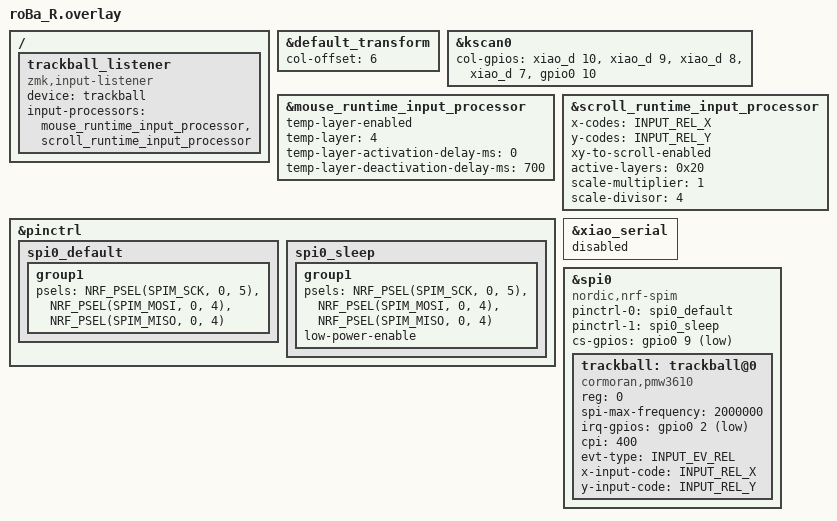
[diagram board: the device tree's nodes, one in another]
#include "roBa.dtsi"
// DYA Studio対応: Runtime Input Processor のノード定義(mouse_/scroll_runtime_input_processor)と
//                 入力イベントコード(INPUT_EV_REL / INPUT_REL_X/Y)を取り込む
#include <input/processors/runtime-input-processor.dtsi>
#include <zephyr/dt-bindings/input/input-event-codes.h>

&default_transform {
    col-offset = <6>;
};

&kscan0 {
        col-gpios
            = <&xiao_d 10 GPIO_ACTIVE_HIGH>
            , <&xiao_d 9 GPIO_ACTIVE_HIGH>
            , <&xiao_d 8 GPIO_ACTIVE_HIGH>
            , <&xiao_d 7 GPIO_ACTIVE_HIGH>
            , <&gpio0 10 GPIO_ACTIVE_HIGH>
            ;
};

/ {
    trackball_listener {
        status = "okay";
        compatible = "zmk,input-listener";
        device = <&trackball>;
        // DYA Studio対応: mouse → scroll の2段チェーン。
        //   mouse は全レイヤーで有効 (Temp-Layer で auto mouse layer を実現)。
        //   scroll は active-layers のレイヤーでのみ変換し、それ以外は素通し。
        //   どちらも DYA Studio から実行時に変更できる。
        input-processors = <&mouse_runtime_input_processor &scroll_runtime_input_processor>;
    };
};

// DYA Studio対応: auto mouse layer (旧 automouse-layer=<4> の代替)
//   トラックボール操作で自動的に MOUSE レイヤー(4)を有効化し、
//   キー押下 or 一定時間操作なしで解除する。値は DYA Studio から変更可能。
&mouse_runtime_input_processor {
    temp-layer-enabled;
    temp-layer = <4>;                       // MOUSE レイヤー
    temp-layer-activation-delay-ms = <0>;   // 操作開始から有効化までの遅延
    temp-layer-deactivation-delay-ms = <700>; // 操作停止から解除までの遅延 (旧 AUTOMOUSE_TIMEOUT 相当)
};

// DYA Studio対応: スクロール (旧 scroll-layers=<5> の代替)
//   トラックボールの生イベント(REL_X/Y)をスクロールに変換。
//   active-layers のビットマスクで有効レイヤーを指定 (bit5 = SCROLL レイヤー(5))。
//   速度・有効レイヤーは DYA Studio から変更可能。
&scroll_runtime_input_processor {
    x-codes = <INPUT_REL_X>;
    y-codes = <INPUT_REL_Y>;
    xy-to-scroll-enabled;
    active-layers = <0x20>;     // 1 << 5 = SCROLL レイヤー(5)
    scale-multiplier = <1>;
    scale-divisor = <4>;        // スクロール速度。大きいほど遅い。
};

&pinctrl {
    spi0_default: spi0_default {
        group1 {
            psels = <NRF_PSEL(SPIM_SCK, 0, 5)>,
                <NRF_PSEL(SPIM_MOSI, 0, 4)>,
                <NRF_PSEL(SPIM_MISO, 0, 4)>;
        };
    };

    spi0_sleep: spi0_sleep {
        group1 {
            psels = <NRF_PSEL(SPIM_SCK, 0, 5)>,
                <NRF_PSEL(SPIM_MOSI, 0, 4)>,
                <NRF_PSEL(SPIM_MISO, 0, 4)>;
            low-power-enable;
        };
    };
};

&xiao_serial { status = "disabled"; };

&spi0 {
    status = "okay";
    compatible = "nordic,nrf-spim";
    pinctrl-0 = <&spi0_default>;
    pinctrl-1 = <&spi0_sleep>;
    pinctrl-names = "default", "sleep";
    cs-gpios = <&gpio0 9 GPIO_ACTIVE_LOW>;

    trackball: trackball@0 {
        status = "okay";
        // DYA Studio対応: cormoran 版ドライバを使う (compatible は cormoran,pmw3610)
        compatible = "cormoran,pmw3610";
        reg = <0>;
        spi-max-frequency = <2000000>;
        irq-gpios = <&gpio0 2 (GPIO_ACTIVE_LOW | GPIO_PULL_UP)>;
        // DYA Studio対応: CPI と入力イベント種別はノード側で指定する
        cpi = <400>;
        evt-type = <INPUT_EV_REL>;
        x-input-code = <INPUT_REL_X>;
        y-input-code = <INPUT_REL_Y>;
    };
};
